# RS1xxxx register map
Vendor: Silicon Lab Inc.; Series: ARMCM4; File version: 1.2
CPU: CM4 r1p0, little endian, MPU, FPU, 6 interrupt priority bits
Registers are 32-bit, read-write, reset 0x0 unless marked. A register's access mark holds for its fields unless they carry their own. Offsets are from the block's base; [hi:lo] are bit positions.

## UULP_Domain_Ctrl_REGs — NPSS has always ON domain logic which is not power gatable Which consistes of power, reset, isolation controls for different power domains in NPSS.
Base 0x24048000
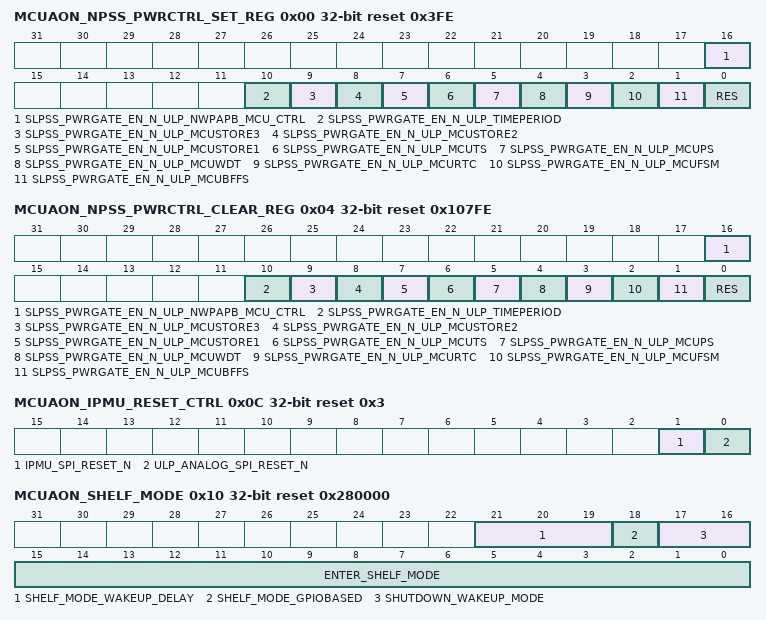
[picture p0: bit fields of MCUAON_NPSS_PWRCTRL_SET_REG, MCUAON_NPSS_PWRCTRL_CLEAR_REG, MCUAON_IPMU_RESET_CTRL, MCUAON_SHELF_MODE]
0x00 MCUAON_NPSS_PWRCTRL_SET_REG reset 0x3FE — This register used for NPSS power control set register.
  [16] SLPSS_PWRGATE_EN_N_ULP_NWPAPB_MCU_CTRL — NWPAPB MCU control power gate enable
  [10] SLPSS_PWRGATE_EN_N_ULP_TIMEPERIOD — TIMEPERIOD power gate enable.
  [9] SLPSS_PWRGATE_EN_N_ULP_MCUSTORE3 — MCU Storage 3 power gate enable for 64-bit.if set,power supply is on,clearing this bit has no effect.
  [8] SLPSS_PWRGATE_EN_N_ULP_MCUSTORE2 — MCU Storage 2 power gate enable for 64-bit.if set,power supply is on,clearing this bit has no effect.
  [7] SLPSS_PWRGATE_EN_N_ULP_MCUSTORE1 — MCU Storage 1 power gate enable for 64-bit.if set,power supply is on,clearing this bit has no effect.
  [6] SLPSS_PWRGATE_EN_N_ULP_MCUTS — MCU temperature sensor power gate enable if set,power supply is on.clearing this bit has no effect
  [5] SLPSS_PWRGATE_EN_N_ULP_MCUPS — MCU PS power gate enable.if set,power supply is on clearing this bit has no effect.
  [4] SLPSS_PWRGATE_EN_N_ULP_MCUWDT — MCU WDT power gate enable if set,power supply is on clearing this bit has no effect
  [3] SLPSS_PWRGATE_EN_N_ULP_MCURTC — MCU RTC power gate enable if set,power supply is on clearing this bit has no effect.
  [2] SLPSS_PWRGATE_EN_N_ULP_MCUFSM — MCU FSM power gate enable,If set power supply is on clearing this bit has no effect.
  [1] SLPSS_PWRGATE_EN_N_ULP_MCUBFFS — MCU domain battery FF's power gate enable.If set,Power Supply is On clearing this bit has no effect.
  [0] RES — bit is reserved
0x04 MCUAON_NPSS_PWRCTRL_CLEAR_REG reset 0x107FE — This register used for NPSS power control clear register.
  [16] SLPSS_PWRGATE_EN_N_ULP_NWPAPB_MCU_CTRL — NWPAPB MCU control power gate enable
  [10] SLPSS_PWRGATE_EN_N_ULP_TIMEPERIOD — TIMEPERIOD power gate enable.
  [9] SLPSS_PWRGATE_EN_N_ULP_MCUSTORE3 — MCU Storage 3 power gate enable for 64-bit.if set,power supply is OFF,clearing this bit has no effect.
  [8] SLPSS_PWRGATE_EN_N_ULP_MCUSTORE2 — MCU Storage 2 power gate enable for 64-bit.if set,power supply is OFF,clearing this bit has no effect.
  [7] SLPSS_PWRGATE_EN_N_ULP_MCUSTORE1 — MCU Storage 1 power gate enable for 64-bit.if set,power supply is OFF,clearing this bit has no effect.
  [6] SLPSS_PWRGATE_EN_N_ULP_MCUTS — MCU temperature sensor power gate enable if set,power supply is OFF.clearing this bit has no effect
  [5] SLPSS_PWRGATE_EN_N_ULP_MCUPS — MCU PS power gate enable.if set,power supply is OFF clearing this bit has no effect.
  [4] SLPSS_PWRGATE_EN_N_ULP_MCUWDT — MCU WDT power gate enable if set,power supply is OFF clearing this bit has no effect
  [3] SLPSS_PWRGATE_EN_N_ULP_MCURTC — MCU RTC power gate enable if set,power supply is OFF clearing this bit has no effect.
  [2] SLPSS_PWRGATE_EN_N_ULP_MCUFSM — MCU FSM power gate enable,If set power supply is OFF clearing this bit has no effect.
  [1] SLPSS_PWRGATE_EN_N_ULP_MCUBFFS — MCU domain battery FF's power gate enable.If set,Power Supply is OFF clearing this bit has no effect.
  [0] RES — bit is reserved
0x0C MCUAON_IPMU_RESET_CTRL reset 0x3 — This register used for ipmu reset control register
  [1] IPMU_SPI_RESET_N — IPMU SPI Reset Signal,if bit is 1 then outoff reset,else in reset
  [0] ULP_ANALOG_SPI_RESET_N — ULP Analog SPI Reset Signal, if bit is 1 then outoff reset,else in reset
0x10 MCUAON_SHELF_MODE reset 0x280000 — This register used for control shelf mode.
  [21:19] SHELF_MODE_WAKEUP_DELAY — Programmable delay for resetting Chip during exit phase of shelf mode.
  [18] SHELF_MODE_GPIOBASED — GPIO based shelf mode entering,If set 1 by processor, On Falling edge of GPIO (Based on the option used in shutdown_wakeup_mode register) chip will enter Shelf mode.
  [17:16] SHUTDOWN_WAKEUP_MODE — GPIO based wakeup mode configuration.
  [15:0] ENTER_SHELF_MODE wo — Program 0xAAAA for entering shelf mode.
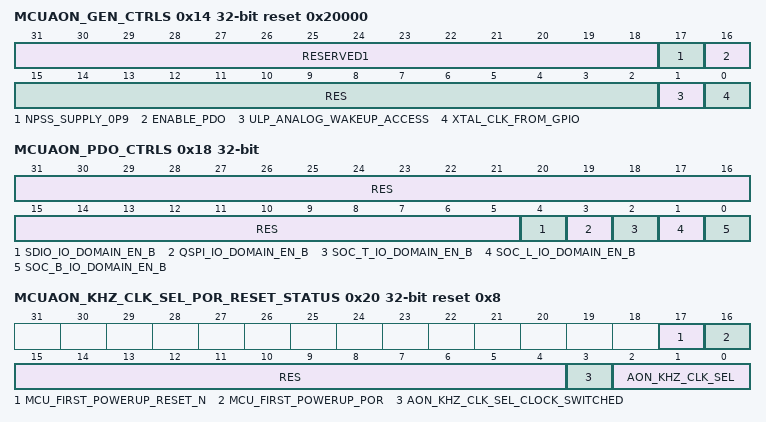
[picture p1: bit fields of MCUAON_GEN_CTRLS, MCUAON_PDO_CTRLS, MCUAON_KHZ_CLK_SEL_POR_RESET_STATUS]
0x14 MCUAON_GEN_CTRLS reset 0x20000 — This register used for MCUON gen control mode.
  [31:18] RESERVED1 — reser
  [17] NPSS_SUPPLY_0P9 — keep npss supply always at 0.9V,if bit is 1 then npss supply always at 0.9V else bit is zero then npss supply will switch from 0.6V to 0.9V based on high frequency enables.
  [16] ENABLE_PDO — Enable turning Off POD power domain when SOC_LDO EN is low,When Set to 1, Up on SoC LDO Enable going low, IO supply (3.3v)to SOC Pads will be tuned-off.
  [15:2] RES — reser
  [1] ULP_ANALOG_WAKEUP_ACCESS — ULP analog wakeup Source Access,if bit is 1 then TASS else bit is 0 then M4SS.
  [0] XTAL_CLK_FROM_GPIO — Select external 32KHz clock from NPSS GPIO's,if bit is 1 then select XTAL clock from GPIO Pins. Please refer to NPSS GPIO Pin muxing for configuration.else select XTAL clock from IPMU clock sources.
0x18 MCUAON_PDO_CTRLS — This register used for MCUON PDO control mode.
  [31:5] RES — reser
  [4] SDIO_IO_DOMAIN_EN_B — Turn-Off IO supply of SDIO domain.,if bit is 1 then turn-off and 0 then turn on
  [3] QSPI_IO_DOMAIN_EN_B — Turn-Off IO supply of QSPI domain,if bit is 1 then turn-off and 0 then turn on
  [2] SOC_T_IO_DOMAIN_EN_B — Turn-Off IO supply of SOC domain on top side,if bit is 1 then turn-off and 0 then turn on
  [1] SOC_L_IO_DOMAIN_EN_B — Turn-Off IO supply of SOC domain on left side,if bit is 1 then turn-off and 0 then turn on
  [0] SOC_B_IO_DOMAIN_EN_B — Turn-Off IO supply of SOC domain on bottom side,if bit is 1 then turn-off and 0 then turn on
0x1C MCUAON_WDT_CHIP_RST reset 0x1 — This register used for wdt chip reset purpose.
  [0] MCU_WDT_BASED_CHIP_RESET — When cleared, Up on host reset request.Power-On Reset (POR) will be generated
0x20 MCUAON_KHZ_CLK_SEL_POR_RESET_STATUS reset 0x8 — This register used for khz clock select and reset status
  [17] MCU_FIRST_POWERUP_RESET_N — Program this bit to '1' upon power_up,It will be clear when reset pin is pulled low.
  [16] MCU_FIRST_POWERUP_POR — Program this bit to '1' upon power_up.It will be clear when Vbatt power is removed
  [15:4] RES — reser
  [3] AON_KHZ_CLK_SEL_CLOCK_SWITCHED ro — If Khz clock mux select is modified,please poll this bit and wait till it becomes one.
  [2:0] AON_KHZ_CLK_SEL — NPSS AON KHz clock selection,if 001 Khz RO clock select,else if 010 - Khz RC clock select,else 100 Khz Xtal clock select
